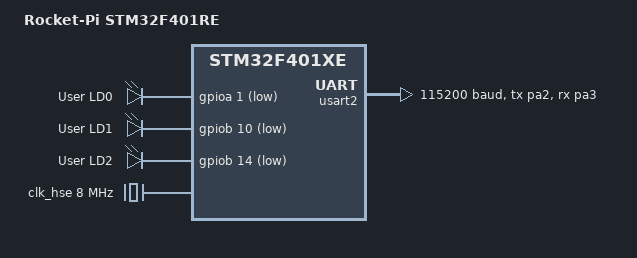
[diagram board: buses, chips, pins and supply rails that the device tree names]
/*
 * SPDX-License-Identifier: Apache-2.0
 */

/dts-v1/;
#include <st/f4/stm32f401Xe.dtsi>
#include <st/f4/stm32f401r(d-e)tx-pinctrl.dtsi>

/ {
	model = "Rocket-Pi STM32F401RE";
	compatible = "newbie-jiang,rocket-pi";

	chosen {
		zephyr,console = &usart2;
		zephyr,shell-uart = &usart2;
		zephyr,sram = &sram0;
		zephyr,flash = &flash0;
	};

	leds {
		compatible = "gpio-leds";

		red_led: led_0 {
			gpios = <&gpioa 1 GPIO_ACTIVE_LOW>;
			label = "User LD0";
		};

		green_led: led_1 {
			gpios = <&gpiob 10 GPIO_ACTIVE_LOW>;
			label = "User LD1";
		};

		blue_led: led_2 {
			gpios = <&gpiob 14 GPIO_ACTIVE_LOW>;
			label = "User LD2";
		};
	};

	aliases {
		led0 = &red_led;
		led1 = &green_led;
		led2 = &blue_led;
	};
};

&clk_lsi {
	status = "okay";
};

&clk_hse {
	clock-frequency = <DT_FREQ_M(8)>;
	status = "okay";
};

&pll {
	div-m = <4>;
	mul-n = <168>;
	div-p = <4>;
	div-q = <7>;
	clocks = <&clk_hse>;
	status = "okay";
};

&rcc {
	clocks = <&pll>;
	clock-frequency = <DT_FREQ_M(84)>;
	ahb-prescaler = <1>;
	apb1-prescaler = <2>;
	apb2-prescaler = <1>;
};

&usart2 {
	pinctrl-0 = <&usart2_tx_pa2 &usart2_rx_pa3>;
	pinctrl-names = "default";
	current-speed = <115200>;
	status = "okay";
};

&flash0 {
	partitions {
		compatible = "fixed-partitions";
		#address-cells = <1>;
		#size-cells = <1>;

		boot_partition: partition@0 {
			label = "mcuboot";
			reg = <0x00000000 DT_SIZE_K(64)>;
			read-only;
		};

		slot0_partition: partition@20000 {
			label = "image-0";
			reg = <0x00020000 DT_SIZE_K(128)>;
		};

		slot1_partition: partition@40000 {
			label = "image-1";
			reg = <0x00040000 DT_SIZE_K(128)>;
		};

		scratch_partition: partition@60000 {
			label = "image-scratch";
			reg = <0x00060000 DT_SIZE_K(128)>;
		};
	};
};
